# ATxmega256A3BU device description
Architecture: AVR8_XMEGA; Family: AVR XMEGA
Registers are 8-bit, access not given, no defined reset value unless marked. A register's access mark holds for its fields unless they carry their own. Offsets are from the block's base; [hi:lo] are bit positions; {n}, {i} and the like mark numbered series; 'fields as' and 'values as' point back to an identical list.

## DAC — Digital-to-Analog Converter
Instances: DACB 0x0320
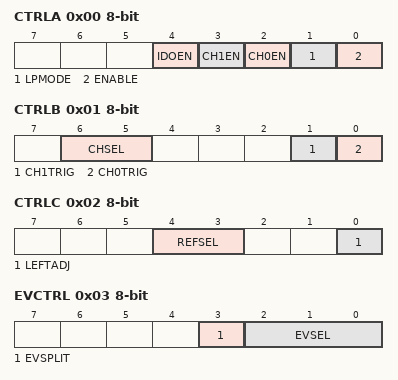
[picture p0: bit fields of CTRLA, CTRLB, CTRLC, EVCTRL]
0x00 CTRLA — Control Register A
  [4] IDOEN — Internal Output Enable
  [3] CH1EN — Channel 1 Output Enable
  [2] CH0EN — Channel 0 Output Enable
  [1] LPMODE — Low Power Mode
  [0] ENABLE
0x01 CTRLB — Control Register B
  [6:5] CHSEL — Channel Select
    0=SINGLE (Single channel operation (Channel 0 only)); 1=SINGLE1 (Single channel operation (Channel 1 only)); 2=DUAL (Dual channel operation (Channel 0 and channel 1))
  [1] CH1TRIG — Channel 1 Event Trig Enable
  [0] CH0TRIG — Channel 0 Event Trig Enable
0x02 CTRLC — Control Register C
  [4:3] REFSEL — Reference Select
    0=INT1V (Internal 1V); 1=AVCC (Analog supply voltage); 2=AREFA (External reference on AREF on PORTA); 3=AREFB (External reference on AREF on PORTB)
  [0] LEFTADJ — Left-adjust Result
0x03 EVCTRL — Event Input Control
  [3] EVSPLIT — Separate Event Channel Input for Channel 1
  [2:0] EVSEL — Event Input Selection
    {v}=Event Channel {v} (v=0..7)
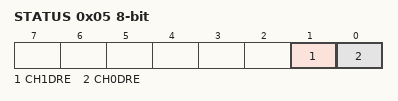
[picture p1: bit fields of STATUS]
0x05 STATUS
  [1] CH1DRE — Channel 1 Data Register Empty
  [0] CH0DRE — Channel 0 Data Register Empty
0x08 CH0GAINCAL — Gain Calibration
  [6:0] CH0GAINCAL
0x09 CH0OFFSETCAL — Offset Calibration
  [6:0] CH0OFFSETCAL
0x0A CH1GAINCAL — Gain Calibration
  [6:0] CH1GAINCAL
0x0B CH1OFFSETCAL — Offset Calibration
  [6:0] CH1OFFSETCAL
0x18 CH0DATA 16-bit — Channel 0 Data
0x1A CH1DATA 16-bit — Channel 1 Data

## AC — Analog Comparator
Instances: ACA 0x0380, ACB 0x0390
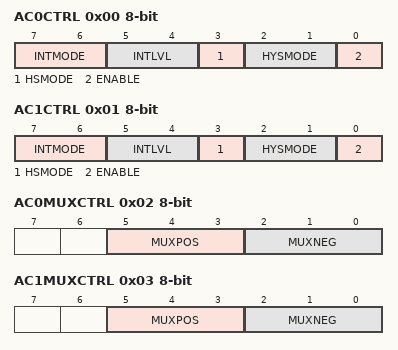
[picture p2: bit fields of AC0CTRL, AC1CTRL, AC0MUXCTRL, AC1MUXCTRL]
0x00 AC0CTRL — Analog Comparator 0 Control
  [7:6] INTMODE — Interrupt Mode
    0=BOTHEDGES (Interrupt on both edges); 2=FALLING (Interrupt on falling edge); 3=RISING (Interrupt on rising edge)
  [5:4] INTLVL — Interrupt Level
    0=OFF (Interrupt disabled); 1=LO (Low level); 2=MED (Medium level); 3=HI (High level)
  [3] HSMODE — High-speed Mode
  [2:1] HYSMODE — Hysteresis Mode
    0=NO (No hysteresis); 1=SMALL (Small hysteresis); 2=LARGE (Large hysteresis)
  [0] ENABLE
0x01 AC1CTRL — Analog Comparator 1 Control
  fields as AC0CTRL
0x02 AC0MUXCTRL — Analog Comparator 0 MUX Control
  [5:3] MUXPOS — MUX Positive Input
    {v}=PIN{v} (v=0..6); 7=DAC (DAC output)
  [2:0] MUXNEG — MUX Negative Input
    0=PIN0; 1=PIN1; 2=PIN3; 3=PIN5; 4=PIN7; 5=DAC (DAC output); 6=BANDGAP (Bandgap Reference); 7=SCALER (Internal voltage scaler)
0x03 AC1MUXCTRL — Analog Comparator 1 MUX Control
  fields as AC0MUXCTRL
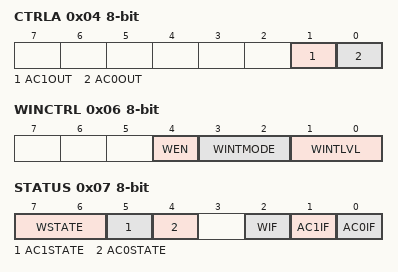
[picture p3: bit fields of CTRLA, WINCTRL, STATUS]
0x04 CTRLA — Control Register A
  [1] AC1OUT — Analog Comparator 1 Output Enable
  [0] AC0OUT — Analog Comparator 0 Output Enable
0x05 CTRLB — Control Register B
  [5:0] SCALEFAC — VCC Voltage Scaler Factor
0x06 WINCTRL — Window Mode Control
  [4] WEN — Window Mode Enable
  [3:2] WINTMODE — Window Interrupt Mode
    0=ABOVE (Interrupt on above window); 1=INSIDE (Interrupt on inside window); 2=BELOW (Interrupt on below window); 3=OUTSIDE (Interrupt on outside window)
  [1:0] WINTLVL — Window Interrupt Level
    0=OFF (Interrupt disabled); 1=LO (Low priority); 2=MED (Medium priority); 3=HI (High priority)
0x07 STATUS
  [7:6] WSTATE — Window Mode State
    0=ABOVE (Signal above window); 1=INSIDE (Signal inside window); 2=BELOW (Signal below window)
  [5] AC1STATE — Analog Comparator 1 State
  [4] AC0STATE — Analog Comparator 0 State
  [2] WIF — Window Mode Interrupt Flag
  [1] AC1IF — Analog Comparator 1 Interrupt Flag
  [0] AC0IF — Analog Comparator 0 Interrupt Flag

## RTC32 — 32-bit Real-Time Counter
Instances: RTC32 0x0420
0x00 CTRL — Control Register
  [0] ENABLE — RTC enable
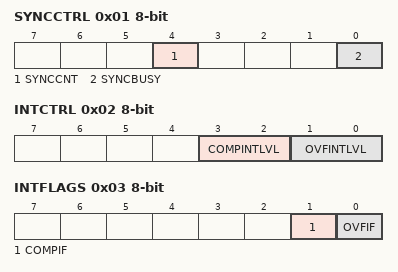
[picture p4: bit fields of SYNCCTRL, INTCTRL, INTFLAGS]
0x01 SYNCCTRL — Synchronization Control/Status Register
  [4] SYNCCNT — Synchronization Busy Flag
  [0] SYNCBUSY — Synchronization Busy Flag
0x02 INTCTRL — Interrupt Control Register
  [3:2] COMPINTLVL — Compare Match Interrupt Level
    0=OFF (Interrupt Disabled); 1=LO (Low Level); 2=MED (Medium Level); 3=HI (High Level)
  [1:0] OVFINTLVL — Overflow Interrupt Level
    values as COMPINTLVL
0x03 INTFLAGS — Interrupt Flags
  [1] COMPIF — Compare Match Interrupt Flag
  [0] OVFIF — Overflow Interrupt Flag
0x04 CNT 32-bit — Count Register
0x08 PER 32-bit — Period Register
0x0C COMP 32-bit — Compare Register
